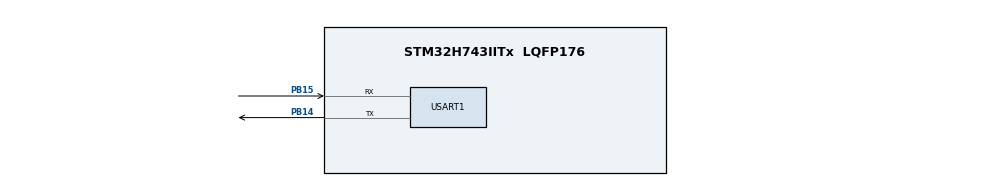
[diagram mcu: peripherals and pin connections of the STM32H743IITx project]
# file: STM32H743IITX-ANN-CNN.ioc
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Dma.Request0=USART1_RX
Dma.Request1=USART1_TX
Dma.USART1_RX.0.Direction=DMA_PERIPH_TO_MEMORY
Dma.USART1_RX.0.EventEnable=DISABLE
Dma.USART1_RX.0.FIFOMode=DMA_FIFOMODE_DISABLE
Dma.USART1_RX.0.Instance=DMA1_Stream0
Dma.USART1_RX.0.MemDataAlignment=DMA_MDATAALIGN_BYTE
Dma.USART1_RX.0.MemInc=DMA_MINC_ENABLE
Dma.USART1_RX.0.Mode=DMA_NORMAL
Dma.USART1_RX.0.PeriphDataAlignment=DMA_PDATAALIGN_BYTE
Dma.USART1_RX.0.PeriphInc=DMA_PINC_DISABLE
Dma.USART1_RX.0.Polarity=HAL_DMAMUX_REQ_GEN_RISING
Dma.USART1_RX.0.Priority=DMA_PRIORITY_HIGH
Dma.USART1_RX.0.RequestNumber=1
Dma.USART1_RX.0.SignalID=NONE
Dma.USART1_RX.0.SyncEnable=DISABLE
Dma.USART1_RX.0.SyncPolarity=HAL_DMAMUX_SYNC_NO_EVENT
Dma.USART1_RX.0.SyncRequestNumber=1
Dma.USART1_RX.0.SyncSignalID=NONE
Dma.USART1_TX.1.Direction=DMA_MEMORY_TO_PERIPH
Dma.USART1_TX.1.EventEnable=DISABLE
Dma.USART1_TX.1.FIFOMode=DMA_FIFOMODE_DISABLE
Dma.USART1_TX.1.Instance=DMA1_Stream1
Dma.USART1_TX.1.MemDataAlignment=DMA_MDATAALIGN_BYTE
Dma.USART1_TX.1.MemInc=DMA_MINC_ENABLE
Dma.USART1_TX.1.Mode=DMA_NORMAL
Dma.USART1_TX.1.PeriphDataAlignment=DMA_PDATAALIGN_BYTE
Dma.USART1_TX.1.PeriphInc=DMA_PINC_DISABLE
Dma.USART1_TX.1.Polarity=HAL_DMAMUX_REQ_GEN_RISING
Dma.USART1_TX.1.Priority=DMA_PRIORITY_HIGH
Dma.USART1_TX.1.RequestNumber=1
Dma.USART1_TX.1.SignalID=NONE
Dma.USART1_TX.1.SyncEnable=DISABLE
Dma.USART1_TX.1.SyncPolarity=HAL_DMAMUX_SYNC_NO_EVENT
Dma.USART1_TX.1.SyncRequestNumber=1
Dma.USART1_TX.1.SyncSignalID=NONE
FREERTOS.Tasks01=defaultTask,24,128,StartDefaultTask,Default,NULL,Dynamic,NULL,NULL;myTask02,8,128,StartTask02,Default,NULL,Dynamic,NULL,NULL
FREERTOS.configENABLE_FPU=1
FREERTOS.configUSE_NEWLIB_REENTRANT=1
Mcu.Family=STM32H7
Mcu.Name=STM32H743IITx
Mcu.Package=LQFP176
NVIC.DMA1_Stream0_IRQn=true\:5\:0\:false\:false\:true\:true\:false\:true\:true
NVIC.DMA1_Stream1_IRQn=true\:5\:0\:false\:false\:true\:true\:false\:true\:true
NVIC.PriorityGroup=NVIC_PRIORITYGROUP_4
NVIC.USART1_IRQn=true\:5\:0\:false\:false\:true\:true\:true\:true\:true
PB14.Mode=Asynchronous
PB14.Signal=USART1_TX
PB15.Mode=Asynchronous
PB15.Signal=USART1_RX
ProjectManager.HeapSize=0x200
ProjectManager.StackSize=0x400
ProjectManager.TargetToolchain=STM32CubeIDE
RCC.ADCFreq_Value=129000000
RCC.APB1Freq_Value=64000000
RCC.APB2Freq_Value=32000000
RCC.APB3Freq_Value=64000000
RCC.APB4Freq_Value=64000000
RCC.CortexFreq_Value=64000000
RCC.D2PPRE2=RCC_APB2_DIV2
RCC.HCLKFreq_Value=64000000
RCC.SYSCLKFreq_VALUE=64000000
RCC.USBFreq_Value=129000000
USART1.VirtualMode-Asynchronous=VM_ASYNC
VP_FREERTOS_VS_CMSIS_V2.Mode=CMSIS_V2
board=custom

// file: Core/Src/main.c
/* USER CODE BEGIN Header */
/**
  ******************************************************************************
  * @file           : main.c
  * @brief          : Main program body
  ******************************************************************************
  * @attention
  *
  * Copyright (c) 2023 STMicroelectronics.
  * All rights reserved.
  *
  * This software is licensed under terms that can be found in the LICENSE file
  * in the root directory of this software component.
  * If no LICENSE file comes with this software, it is provided AS-IS.
  *
  ******************************************************************************
  */
/* USER CODE END Header */
#include "main.h"
#include "cmsis_os.h"
#include "dma.h"
#include "usart.h"
#include "gpio.h"

void SystemClock_Config(void);
void MX_FREERTOS_Init(void);

int main(void)
{

  /* MCU Configuration--------------------------------------------------------*/

  /* Reset of all peripherals, Initializes the Flash interface and the Systick. */
  HAL_Init();

  /* Configure the system clock */
  SystemClock_Config();

  /* Initialize all configured peripherals */
  MX_GPIO_Init();
  MX_DMA_Init();
  MX_USART1_UART_Init();

  /* Init scheduler */
  osKernelInitialize();  /* Call init function for freertos objects (in freertos.c) */
  MX_FREERTOS_Init();

  /* Start scheduler */
  osKernelStart();

  /* We should never get here as control is now taken by the scheduler */
  /* Infinite loop */
  while (1)
  {

  }
}

void SystemClock_Config(void)
{
  RCC_OscInitTypeDef RCC_OscInitStruct = {0};
  RCC_ClkInitTypeDef RCC_ClkInitStruct = {0};

  /** Supply configuration update enable
  */
  HAL_PWREx_ConfigSupply(PWR_LDO_SUPPLY);

  /** Configure the main internal regulator output voltage
  */
  __HAL_PWR_VOLTAGESCALING_CONFIG(PWR_REGULATOR_VOLTAGE_SCALE3);

  while(!__HAL_PWR_GET_FLAG(PWR_FLAG_VOSRDY)) {}

  /** Initializes the RCC Oscillators according to the specified parameters
  * in the RCC_OscInitTypeDef structure.
  */
  RCC_OscInitStruct.OscillatorType = RCC_OSCILLATORTYPE_HSI;
  RCC_OscInitStruct.HSIState = RCC_HSI_DIV1;
  RCC_OscInitStruct.HSICalibrationValue = RCC_HSICALIBRATION_DEFAULT;
  RCC_OscInitStruct.PLL.PLLState = RCC_PLL_NONE;
  if (HAL_RCC_OscConfig(&RCC_OscInitStruct) != HAL_OK)
  {
    Error_Handler();
  }

  /** Initializes the CPU, AHB and APB buses clocks
  */
  RCC_ClkInitStruct.ClockType = RCC_CLOCKTYPE_HCLK|RCC_CLOCKTYPE_SYSCLK
                              |RCC_CLOCKTYPE_PCLK1|RCC_CLOCKTYPE_PCLK2
                              |RCC_CLOCKTYPE_D3PCLK1|RCC_CLOCKTYPE_D1PCLK1;
  RCC_ClkInitStruct.SYSCLKSource = RCC_SYSCLKSOURCE_HSI;
  RCC_ClkInitStruct.SYSCLKDivider = RCC_SYSCLK_DIV1;
  RCC_ClkInitStruct.AHBCLKDivider = RCC_HCLK_DIV1;
  RCC_ClkInitStruct.APB3CLKDivider = RCC_APB3_DIV1;
  RCC_ClkInitStruct.APB1CLKDivider = RCC_APB1_DIV1;
  RCC_ClkInitStruct.APB2CLKDivider = RCC_APB2_DIV2;
  RCC_ClkInitStruct.APB4CLKDivider = RCC_APB4_DIV1;

  if (HAL_RCC_ClockConfig(&RCC_ClkInitStruct, FLASH_LATENCY_1) != HAL_OK)
  {
    Error_Handler();
  }
}

void Error_Handler(void)
{
  __disable_irq();
  while (1)
  {
  }
}

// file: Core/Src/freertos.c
/* USER CODE BEGIN Header */
/**
  ******************************************************************************
  * File Name          : freertos.c
  * Description        : Code for freertos applications
  ******************************************************************************
  * @attention
  *
  * Copyright (c) 2023 STMicroelectronics.
  * All rights reserved.
  *
  * This software is licensed under terms that can be found in the LICENSE file
  * in the root directory of this software component.
  * If no LICENSE file comes with this software, it is provided AS-IS.
  *
  ******************************************************************************
  */
/* USER CODE END Header */

#include "FreeRTOS.h"
#include "task.h"
#include "main.h"
#include "cmsis_os.h"

/* USER CODE BEGIN Includes */
#include "octopus.h"
#include "usart.h"
/* USER CODE END Includes */

/* Definitions for defaultTask */
osThreadId_t defaultTaskHandle;
const osThreadAttr_t defaultTask_attributes = {
  .name = "defaultTask",
  .stack_size = 128 * 4,
  .priority = (osPriority_t) osPriorityNormal,
};
/* Definitions for myTask02 */
osThreadId_t myTask02Handle;
const osThreadAttr_t myTask02_attributes = {
  .name = "myTask02",
  .stack_size = 128 * 4,
  .priority = (osPriority_t) osPriorityLow,
};

void StartDefaultTask(void *argument);
void StartTask02(void *argument);

void MX_FREERTOS_Init(void); /* (MISRA C 2004 rule 8.1) */

void MX_FREERTOS_Init(void) {

  /* Create the thread(s) */
  /* creation of defaultTask */
  defaultTaskHandle = osThreadNew(StartDefaultTask, NULL, &defaultTask_attributes);

  /* creation of myTask02 */
  myTask02Handle = osThreadNew(StartTask02, NULL, &myTask02_attributes);

}

void StartDefaultTask(void *argument)
{
  for(;;)
  {
    osDelay(1);
  }
}

void StartTask02(void *argument)
{
  /* USER CODE BEGIN StartTask02 */
  /* Infinite loop */
  for(;;)
  {
    osDelay(1);
    mv_shell_task(argument);
  }
  /* USER CODE END StartTask02 */
}
